# TC37XPD register map
Vendor: Infineon; Series: ATVMC; File version: 100
CPU: other r0p0, little endian, MPU, FPU, vendor SysTick, 4 interrupt priority bits
Registers are 32-bit, read-write, reset 0x0 unless marked. A register's access mark holds for its fields unless they carry their own. Offsets are from the block's base; [hi:lo] are bit positions; {n}, {i} and the like mark numbered series.

## HSM — Hardware Security Module
Base 0xF0040000
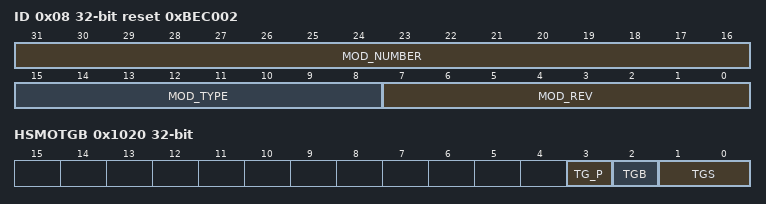
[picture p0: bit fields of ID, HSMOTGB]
0x08 ID ro reset 0xBEC002 — HSM Identifier Register resetvalue={Application Reset:0x0BEC002}
  [31:16] MOD_NUMBER — Module Number Value. This bit field defines a module identification number. The value for the HSM module is 00BE .
  [15:8] MOD_TYPE — Module Type. The bit field is set to C0 which defines the module as a 32 bit module.
  [7:0] MOD_REV — Module Revision Number. This bit field defines the module revision number. The value of a module revision starts with 01 first revision .
0x20 HT2HSMF — Host to HSM Flags resetvalue={Application Reset:0x0}
  [31:0] HT2HSMF — Host to HSM Flags. Each flag can be individually set by the host to generate an HSM interrupt request if the corresponding interrupt enable flag is set. The HSM can clear the flags individually. If a simultaneous the host performs a set and HSM a clear the value of the flag is 8216 1 8217 .
0x28 HSM2HTF — HSM to Host Flags resetvalue={Application Reset:0x0}
  [31:0] HSM2HTF — HSM to Host Flags. Each flag can be individually set by the HSM to generate an host interrupt request if the corresponding interrupt enable flag is set. The host can reset the flags individually by writing 8216 1 8217 . If a simultaneous set and reset occurs the value of the flag is 8216 1 8217 .
0x2C HSM2HTIE — HSM to Host Interrupt Enable resetvalue={Application Reset:0x0}
  [31:0] HSM2HTIE — HSM to Host Interrupt Enable. Each set bit enables the interrupt for the corresponding flags in register HSM HSM2HTF 104HSM2HTF . If cleared bit disables the interrupt.
0x30 HSM2HTIS — HSM to Host Interrupt Select resetvalue={Application Reset:0x0}
  [31:0] HSM2HTIS — HSM to Host Interrupt Select. If a bit is set the corresponding interrupt controlled by registers HSM HSM2HTF 104HSM2HTF and HSM2HTIE is mapped to host interrupt 1 otherwise to host interrupt 0.
0x34 HSM2HTS ro — HSM to Host Status resetvalue={Application Reset:0x0}
  [31:0] HSM2HTS — HSM to Host Status. 32 bits of information to signal HSM internal status to the host.
0x38 HT2HSMS — Host to HSM Status resetvalue={Application Reset:0x0}
  [31:0] HT2HSMS — Host to HSM Status. 32 bits of status information to signal the host software status to the HSM.
0x1000 HSMCTRL — HSM Control resetvalue={Application Reset:0x0}
  [1:0] EOMBT — End of Memory BIST test.. For security reasons this functionality is encoded redundantly.
    0=MON0 (MBIST mode activated.); 1=MOFF11 (MBIST mode deactivated. See below.); 2=MOFF22 (MBIST mode deactivated. See below.); 3=MOFF33 (MBIST mode deactivated. Start of HSM subsystem. Cannot be reset by software)
0x1010 DBGBASE — Debug Window Base Address resetvalue={Application Reset:0x0}
  [31:16] BASE — Base Address. Base address for debug memory window. The effective address of a debug access is HSM DBGBASE 133DBGBASE . HSM DBGBASE.BASE 135BASE offset of access address to base of the memory window.
0x1020 HSMOTGB access per field — OCDS Suspend and Trigger Bus Control resetvalue={Application Reset:0x0}
  [3] TG_P wo — TGS TGB Write Protection. TGS and TGB are only overwritten when TG P is set at the same access otherwise unchanged. Reads as 0.
    0=NC0 (No change.); 1=WE1 (Write enable for the current access.)
  [2] TGB rw — OTGB0 1 Bus Select
    0=BUS00 (Trigger Set is output on OTGB0.); 1=BUS11 (Trigger Set is output on OTGB1.)
  [1:0] TGS rw — Trigger Set for OTGB0 1. This module supports only one Trigger Set. The following values are defined
    0=NOTS0 (No Trigger Set output.); 1=TS11 (Trigger Set 1.); 2=TS22 (No Trigger Set output.); 3=TS33 (Trigger Set 1.)

## CONVCTRL — CONVERTER
Base 0xF0025000
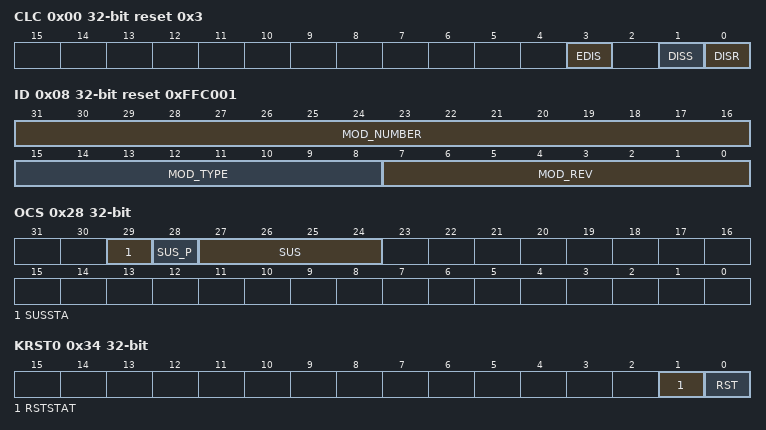
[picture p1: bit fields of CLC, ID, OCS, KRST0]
0x00 CLC access per field reset 0x3 — Clock Control Register resetvalue={Application Reset:0x3}
  [3] EDIS rw — Sleep Mode Enable Control EDIS. Used to control module 8217 s reaction to sleep mode.
  [1] DISS ro — Module Disable Status Bit DISS
  [0] DISR rw — Module Disable Request Bit DISR. Used for enable disable control of the module.
0x08 ID ro reset 0xFFC001 — Module Identification Register resetvalue={PowerOn Reset:0x0FFC001}
  [31:16] MOD_NUMBER — Module Number MOD NUMBER. Indicates the module identification number 00FF CONVCTRL
  [15:8] MOD_TYPE — Module Type MOD TYPE. This internal marker is fixed to C0 .
  [7:0] MOD_REV — Module Revision MOD REV. Indicates the revision number of the implementation. This information depends on the design step.
0x28 OCS access per field — OCDS Control and Status Register resetvalue={PowerOn Reset:0x0,Debug Clear:0x0}
  [29] SUSSTA ro — Suspend State SUSSTA
  [28] SUS_P wo — SUS Write Protection SUS P. SUS is only written when SUS P is 1 otherwise unchanged. Read as 0.
  [27:24] SUS rw — OCDS Suspend Control SUS. Controls the sensitivity to the suspend signal coming from the OCDS Trigger Switch OTGS
0x2C KRSTCLR wo — Kernel Reset Status Clear Register resetvalue={Application Reset:0x0}
  [0] CLR — Kernel Reset Status Clear CLR. Read always as 0.
0x30 KRST1 — Kernel Reset Register 1 resetvalue={Application Reset:0x0}
  [0] RST — Kernel Reset RST. Request a kernel reset. The reset is executed if the reset bits of both kernel reset registers are set. RST is cleared after the kernel reset was executed.
0x34 KRST0 access per field — Kernel Reset Register 0 resetvalue={Application Reset:0x0}
  [1] RSTSTAT ro — Kernel Reset Status RSTSTAT. Indicates an executed kernel reset. RSTSTAT is set after the execution of a kernel reset in the same clock cycle in which the reset bits are cleared. Clear RSTSTAT by setting bit CLR in register KRSTCLR.
  [0] RST rw — Kernel Reset RST. Request a kernel reset. The reset is executed if the reset bits of both kernel reset registers are set. RST is cleared after the kernel reset was executed.
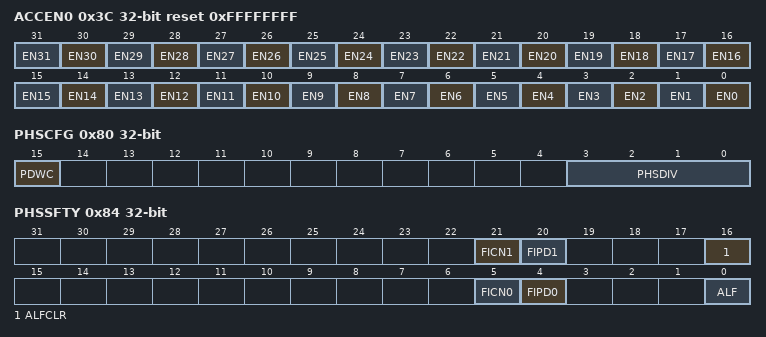
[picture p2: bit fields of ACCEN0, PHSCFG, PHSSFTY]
0x3C ACCEN0 reset 0xFFFFFFFF — Access Enable Register 0 resetvalue={Application Reset:0x0FFFFFFFF}
  [n] EN{n} (n=0..31) — Access Enable for Master TAG ID 31 EN31. This bit enables write access to the module kernel addresses for transactions with the Master TAG ID n
0x7C CCCTRL — Converter Control Block Control Register resetvalue={Application Reset:0x0}
  [31:28] TC — Test Control TC. Not listed combinations write protect CONVCTRL registers.
0x80 PHSCFG access per field — Phase Synchronizer Configuration Register resetvalue={Application Reset:0x0}
  [15] PDWC wo — Write Control for Phase Sync. Divider PDWC. No flipflop required.
  [3:0] PHSDIV rw — Phase Synchronizer Divider PHSDIV. Selects the prescaling factor between the peripheral clock and the phase synchronization signal.
0x84 PHSSFTY access per field — Phase Synchronizer Safety Control Register resetvalue={Application Reset:0x0}
  [21] FICN1 wo — Fault Injection Phase sync Divider
  [20] FIPD1 wo — Fault Injection Phase sync Divider
  [16] ALFCLR wo — Alarm Flag ALF Clear
  [5] FICN0 wo — Fault Injection Counter
  [4] FIPD0 wo — Fault Injection Phase sync Divider
  [0] ALF ro — Alarm Flag for Safety Features. This sticky flag is set when a described error is detected see quot Safety Measures quot it is cleared by writing a quot 1 quot to bit ALFCLR.
